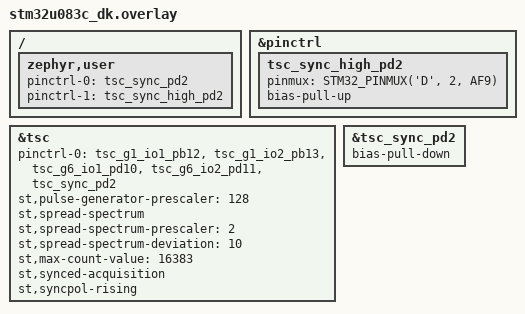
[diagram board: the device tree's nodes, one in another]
/*
 * Copyright (c) 2024 Arif Balik <arifbalik@outlook.com>
 * SPDX-License-Identifier: Apache-2.0
 */

/ {
	zephyr,user {
		/* The test switches the SYNC pin between these two states: pulled low
		 * keeps the synchronized acquisition waiting, pulled high lets it run.
		 */
		pinctrl-0 = <&tsc_sync_pd2>;
		pinctrl-1 = <&tsc_sync_high_pd2>;
		pinctrl-names = "default", "sync_high";
	};
};

&pinctrl {
	tsc_sync_high_pd2: tsc_sync_high_pd2 {
		pinmux = <STM32_PINMUX('D', 2, AF9)>;
		bias-pull-up;
	};
};

&tsc {

	pinctrl-0 = <&tsc_g1_io1_pb12 &tsc_g1_io2_pb13 &tsc_g6_io1_pd10
		     &tsc_g6_io2_pd11 &tsc_sync_pd2>;
	pinctrl-names = "default";

	st,pulse-generator-prescaler = <128>;

	st,spread-spectrum;
	st,spread-spectrum-prescaler = <2>;
	st,spread-spectrum-deviation = <10>;

	st,max-count-value = <16383>;

	st,synced-acquisition;
	st,syncpol-rising;
	status = "okay";
};

/* A floating SYNC pin starts acquisitions on its own, keep it low by default. */
&tsc_sync_pd2 {
	bias-pull-down;
};
